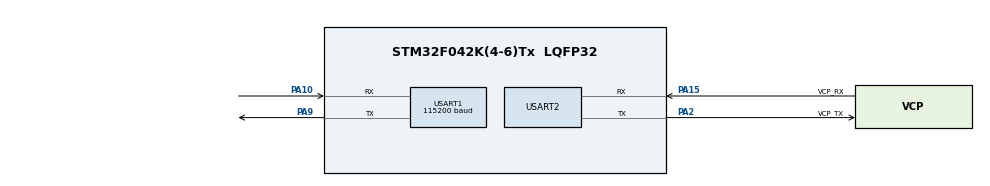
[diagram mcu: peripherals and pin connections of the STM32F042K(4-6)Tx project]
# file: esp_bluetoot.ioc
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Mcu.Family=STM32F0
Mcu.Name=STM32F042K(4-6)Tx
Mcu.Package=LQFP32
PA10.Mode=Asynchronous
PA10.Signal=USART1_RX
PA13.GPIO_Label=SWDIO
PA13.Mode=Serial_Wire
PA13.Signal=SYS_SWDIO
PA14.GPIO_Label=SWCLK
PA14.Mode=Serial_Wire
PA14.Signal=SYS_SWCLK
PA15.GPIO_Label=VCP_RX
PA15.Mode=Asynchronous
PA15.Signal=USART2_RX
PA2.GPIO_Label=VCP_TX
PA2.Mode=Asynchronous
PA2.Signal=USART2_TX
PA9.Mode=Asynchronous
PA9.Signal=USART1_TX
PF0-OSC_IN.GPIO_Label=MCO
PF0-OSC_IN.Mode=HSE-External-Clock-Source
PF0-OSC_IN.Signal=RCC_OSC_IN
ProjectManager.HeapSize=0x200
ProjectManager.StackSize=0x400
ProjectManager.TargetToolchain=STM32CubeIDE
USART1.BaudRate=115200
USART1.VirtualMode-Asynchronous=VM_ASYNC
USART2.VirtualMode-Asynchronous=VM_ASYNC
board=NUCLEO-F042K6

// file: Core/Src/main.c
/* USER CODE BEGIN Header */
/**
  ******************************************************************************
  * @file           : main.c
  * @brief          : Main program body
  ******************************************************************************
  * @attention
  *
  * Copyright (c) 2024 STMicroelectronics.
  * All rights reserved.
  *
  * This software is licensed under terms that can be found in the LICENSE file
  * in the root directory of this software component.
  * If no LICENSE file comes with this software, it is provided AS-IS.
  *
  ******************************************************************************
  */
/* USER CODE END Header */
#include "main.h"

UART_HandleTypeDef huart1;
UART_HandleTypeDef huart2;

/* USER CODE BEGIN PV */
uint8_t buffer1[] = {0xFD, 0x55, 0x55, 0x55};
uint8_t buffer2[] = {0xFD, 0xAA, 0xAA, 0xAA};
uint8_t zero[] = {0xFD, 0x00, 0x00, 0x00};
/* USER CODE END PV */

void SystemClock_Config(void);
static void MX_GPIO_Init(void);
static void MX_USART2_UART_Init(void);
static void MX_USART1_UART_Init(void);

int main(void)
{

  /* MCU Configuration--------------------------------------------------------*/

  /* Reset of all peripherals, Initializes the Flash interface and the Systick. */
  HAL_Init();

  /* Configure the system clock */
  SystemClock_Config();

  /* Initialize all configured peripherals */
  MX_GPIO_Init();
  MX_USART2_UART_Init();
  MX_USART1_UART_Init();

  /* Infinite loop */
  while (1)
  {

    /* USER CODE BEGIN 3 */
	  HAL_UART_Transmit(&huart1, buffer1, sizeof(buffer1), HAL_MAX_DELAY);
	  HAL_Delay(500);
	  HAL_UART_Transmit(&huart1, buffer2, sizeof(buffer2), HAL_MAX_DELAY);
	  HAL_Delay(500);
  }
  /* USER CODE END 3 */
}

void SystemClock_Config(void)
{
  RCC_OscInitTypeDef RCC_OscInitStruct = {0};
  RCC_ClkInitTypeDef RCC_ClkInitStruct = {0};
  RCC_PeriphCLKInitTypeDef PeriphClkInit = {0};

  /** Initializes the RCC Oscillators according to the specified parameters
  * in the RCC_OscInitTypeDef structure.
  */
  RCC_OscInitStruct.OscillatorType = RCC_OSCILLATORTYPE_HSI;
  RCC_OscInitStruct.HSIState = RCC_HSI_ON;
  RCC_OscInitStruct.HSICalibrationValue = RCC_HSICALIBRATION_DEFAULT;
  RCC_OscInitStruct.PLL.PLLState = RCC_PLL_NONE;
  if (HAL_RCC_OscConfig(&RCC_OscInitStruct) != HAL_OK)
  {
    Error_Handler();
  }

  /** Initializes the CPU, AHB and APB buses clocks
  */
  RCC_ClkInitStruct.ClockType = RCC_CLOCKTYPE_HCLK|RCC_CLOCKTYPE_SYSCLK
                              |RCC_CLOCKTYPE_PCLK1;
  RCC_ClkInitStruct.SYSCLKSource = RCC_SYSCLKSOURCE_HSI;
  RCC_ClkInitStruct.AHBCLKDivider = RCC_SYSCLK_DIV1;
  RCC_ClkInitStruct.APB1CLKDivider = RCC_HCLK_DIV1;

  if (HAL_RCC_ClockConfig(&RCC_ClkInitStruct, FLASH_LATENCY_0) != HAL_OK)
  {
    Error_Handler();
  }
  PeriphClkInit.PeriphClockSelection = RCC_PERIPHCLK_USART1;
  PeriphClkInit.Usart1ClockSelection = RCC_USART1CLKSOURCE_PCLK1;
  if (HAL_RCCEx_PeriphCLKConfig(&PeriphClkInit) != HAL_OK)
  {
    Error_Handler();
  }
}

static void MX_USART1_UART_Init(void)
{

  huart1.Instance = USART1;
  huart1.Init.BaudRate = 115200;
  huart1.Init.WordLength = UART_WORDLENGTH_8B;
  huart1.Init.StopBits = UART_STOPBITS_1;
  huart1.Init.Parity = UART_PARITY_NONE;
  huart1.Init.Mode = UART_MODE_TX_RX;
  huart1.Init.HwFlowCtl = UART_HWCONTROL_NONE;
  huart1.Init.OverSampling = UART_OVERSAMPLING_16;
  huart1.Init.OneBitSampling = UART_ONE_BIT_SAMPLE_DISABLE;
  huart1.AdvancedInit.AdvFeatureInit = UART_ADVFEATURE_NO_INIT;
  if (HAL_UART_Init(&huart1) != HAL_OK)
  {
    Error_Handler();
  }

}

static void MX_USART2_UART_Init(void)
{

  huart2.Instance = USART2;
  huart2.Init.BaudRate = 38400;
  huart2.Init.WordLength = UART_WORDLENGTH_8B;
  huart2.Init.StopBits = UART_STOPBITS_1;
  huart2.Init.Parity = UART_PARITY_NONE;
  huart2.Init.Mode = UART_MODE_TX_RX;
  huart2.Init.HwFlowCtl = UART_HWCONTROL_NONE;
  huart2.Init.OverSampling = UART_OVERSAMPLING_16;
  huart2.Init.OneBitSampling = UART_ONE_BIT_SAMPLE_DISABLE;
  huart2.AdvancedInit.AdvFeatureInit = UART_ADVFEATURE_NO_INIT;
  if (HAL_UART_Init(&huart2) != HAL_OK)
  {
    Error_Handler();
  }

}

static void MX_GPIO_Init(void)
{

  /* GPIO Ports Clock Enable */
  __HAL_RCC_GPIOF_CLK_ENABLE();
  __HAL_RCC_GPIOA_CLK_ENABLE();

}

void Error_Handler(void)
{
  __disable_irq();
  while (1)
  {
  }
}
